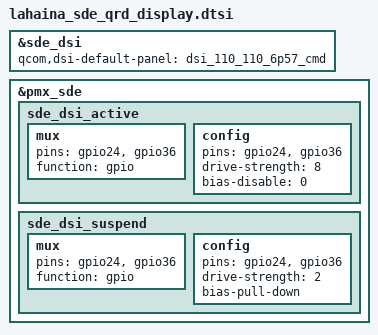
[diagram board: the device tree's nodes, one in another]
#include "dsi-panel-110-110-6p57-cmd.dtsi"
#include "dsi-panel-default-6p57-video.dtsi"
&sde_dsi {
	qcom,dsi-default-panel = <&dsi_110_110_6p57_cmd>;
};

&pmx_sde {
	sde_dsi_active: sde_dsi_active {
		mux {
			pins = "gpio24", "gpio36";
			function = "gpio";
		};

		config {
			pins = "gpio24", "gpio36";
			drive-strength = <8>;   /* 8 mA */
			bias-disable = <0>;   /* no pull */
		};
	};

	sde_dsi_suspend: sde_dsi_suspend {
		mux {
			pins = "gpio24", "gpio36";
			function = "gpio";
		};

		config {
			pins = "gpio24", "gpio36";
			drive-strength = <2>;   /* 2 mA */
			bias-pull-down;         /* PULL DOWN */
		};
	};
};
